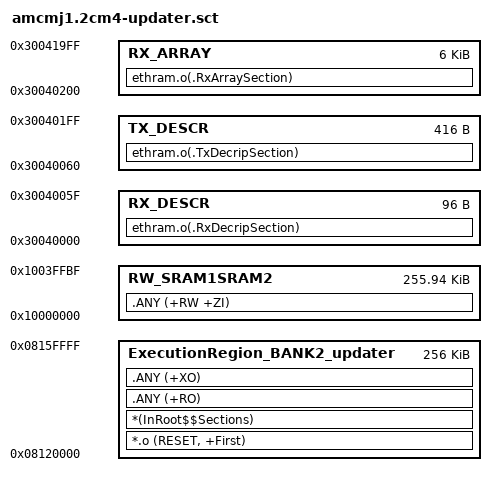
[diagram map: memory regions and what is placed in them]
; amcmj1-updater running on cm4. it uses following FLASH and RAM resources:
; 
; - FLASH: 2nd bank @ 0x08120000 for a size of 256k
; 
; - RAM: RAM: SRAM1-SRAM2 @ 0x10000000 for a size of 256K - 64
; 
; the memory for IPC is @ 0x1003FFC0, on the top 64 bytes of SRAM1-SRAM2 used by the CM4

LoadRegion_BANK2_updater 0x08120000 0x00040000  {  
  
  ; execution region is in flash
  ExecutionRegion_BANK2_updater 0x08120000 0x00040000  {  
   *.o (RESET, +First)
   *(InRoot$$Sections)
   .ANY (+RO)
   .ANY (+XO)
  }

  ; eth mapping. comment it out if ethram.o is not linked
  RX_DESCR	0x30040000 0x00000060 {
  	ethram.o(.RxDecripSection)
  }
  TX_DESCR	0x30040060 0x000001A0 {
  	ethram.o(.TxDecripSection)
  }
  RX_ARRAY 	0x30040200 0x00001800 {
  	ethram.o(.RxArraySection)
  }
    
  ; ram: banks sram1 and sram2 joined together with a 64 bytes hole on top for ipc
  RW_SRAM1SRAM2 0x10000000 0x0003FFC0 {
   .ANY (+RW +ZI)
  }
  
}

